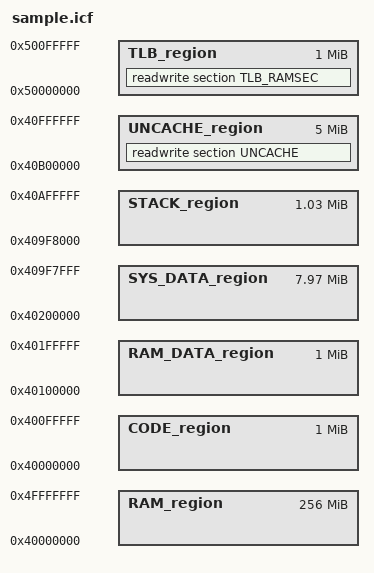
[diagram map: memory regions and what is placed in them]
/*###ICF### Section handled by ICF editor, don't touch! ****/
/*-Editor annotation file-*/
/* IcfEditorFile="$TOOLKIT_DIR$\config\ide\IcfEditor\a_v1_0.xml" */
/*-Specials-*/
define symbol __ICFEDIT_intvec_start__ = 0x40000000;
/*-Memory Regions-*/
define symbol __ICFEDIT_region_ROM_start__   = 0x00000000;
define symbol __ICFEDIT_region_ROM_end__     = 0x00000000;
define symbol __ICFEDIT_region_RAM_start__   = 0x40000000;
define symbol __ICFEDIT_region_RAM_end__     = 0x4FFFFFFF;
/*-Sizes-*/
define symbol __ICFEDIT_size_cstack__   = 0x8000;
define symbol __ICFEDIT_size_svcstack__ = 0x400;
define symbol __ICFEDIT_size_irqstack__ = 0x400;
define symbol __ICFEDIT_size_fiqstack__ = 0x100;
define symbol __ICFEDIT_size_undstack__ = 0x100;
define symbol __ICFEDIT_size_abtstack__ = 0x100;
define symbol __ICFEDIT_size_heap__     = 0x0;
/**** End of ICF editor section. ###ICF###*/
define symbol __region_TLB_RAM_start__   = 0x50000000;
define symbol __region_TLB_RAM_end__     = 0x500FFFFF;
define symbol __region_CODE_start__      = 0x40000000;
define symbol __region_CODE_end__        = 0x400FFFFF;
define symbol __region_RAM_DATA_start__  = 0x40100000;
define symbol __region_RAM_DATA_end__    = 0x401FFFFF;
define symbol __region_SYS_DATA_start__  = 0x40200000;
define symbol __region_SYS_DATA_end__    = 0x409F7FFF;
define symbol __region_STACK_start__     = 0x409F8000;
define symbol __region_STACK_end__       = 0x40AFFFFF;
define symbol __region_UNCACHE_start__   = 0x40B00000;
define symbol __region_UNCACHE_end__     = 0x40FFFFFF;

define memory mem with size = 4G;

define region RAM_region   = mem:[from __ICFEDIT_region_RAM_start__   to __ICFEDIT_region_RAM_end__];
define region TLB_region   = mem:[from __region_TLB_RAM_start__       to __region_TLB_RAM_end__];
define region CODE_region  = mem:[from __region_CODE_start__      to __region_CODE_end__];
define region UNCACHE_region  = mem:[from __region_UNCACHE_start__      to __region_UNCACHE_end__];
define region RAM_DATA_region  = mem:[from __region_RAM_DATA_start__      to __region_RAM_DATA_end__];
define region SYS_DATA_region  = mem:[from __region_SYS_DATA_start__      to __region_SYS_DATA_end__];
define region STACK_region     = mem:[from __region_STACK_start__         to __region_STACK_end__];

define block CSTACK    with alignment = 8, size = __ICFEDIT_size_cstack__   { };
define block SVC_STACK with alignment = 8, size = __ICFEDIT_size_svcstack__ { };
define block IRQ_STACK with alignment = 8, size = __ICFEDIT_size_irqstack__ { };
define block FIQ_STACK with alignment = 8, size = __ICFEDIT_size_fiqstack__ { };
define block UND_STACK with alignment = 8, size = __ICFEDIT_size_undstack__ { };
define block ABT_STACK with alignment = 8, size = __ICFEDIT_size_abtstack__ { };
initialize by copy {  readwrite };
do not initialize  { section .noinit };

place in CODE_region   { block CodeTop with fixed order{
                                                       readonly section .intvec,
                                                       readonly }
                                                         };
place in RAM_DATA_region   { block RamDataTop with fixed order{
                                                        readwrite,
                                                        section VINFTBL,
                                                        section VECTTBL}
                                                        };
place in SYS_DATA_region   { block SysDataTop with fixed order{
                                                        section MPLMEM,
                                                        section STKMEM,
                                                        section SYSMEM,
                                                        section SYS,
                                                        }
                                                        };
place in STACK_region { block StackTop with fixed order {
                             block FIQ_STACK,
                             block UND_STACK,
                             block ABT_STACK,
                             block SVC_STACK,
                             block IRQ_STACK,
                             block CSTACK,
                        }};

place in UNCACHE_region   { readwrite section UNCACHE };
place in TLB_region   { readwrite section TLB_RAMSEC };

